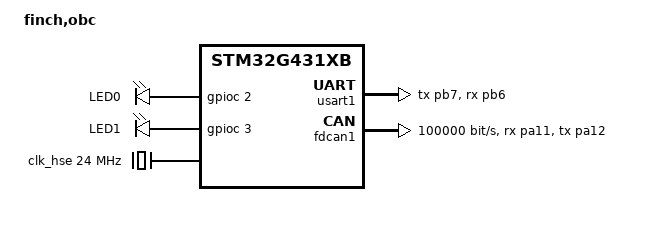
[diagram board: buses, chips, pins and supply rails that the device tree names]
/*
 * Copyright (c) 2025 The FINCH CubeSat Project Flight Software Contributors
 *
 * SPDX-License-Identifier: Apache-2.0
 */

/dts-v1/;

#include <st/g4/stm32g431Xb.dtsi>
#include <dt-bindings/pinctrl/stm32-pinctrl.h>
#include <zephyr/dt-bindings/clock/stm32g4_clock.h>

/ {
	model = "finch,obc";
	compatible = "finch,obc";

	chosen {
		zephyr,sram = &sram0;
		zephyr,flash = &flash0;
		zephyr,code-partition = &slot0_partition;
		zephyr,console = &usart1;
		zephyr,canbus = &fdcan1;
	};

	leds: leds {
		compatible = "gpio-leds";
		act_led: led_0 {
			gpios = <&gpioc 2 GPIO_ACTIVE_HIGH>;
			label = "LED0";
		};
		wrn_led: led_1 {
			gpios = <&gpioc 3 GPIO_ACTIVE_HIGH>;
			label = "LED1";
		};
	};

	aliases {
		led0 = &act_led;
		actled = &act_led;
		led1 = &wrn_led;
		wrnled = &wrn_led;
	};
};

&clk_hse {
	clock-frequency = <DT_FREQ_M(24)>;
	status = "okay";
};

&pll {
	div-m = <6>;
	mul-n = <85>;
	div-p = <7>;
	div-q = <2>;
	div-r = <2>;
	clocks = <&clk_hse>;
	status = "okay";
};

&rcc {
	clocks = <&pll>;
	clock-frequency = <DT_FREQ_M(170)>;
	ahb-prescaler = <1>;
	apb1-prescaler = <1>;
	apb2-prescaler = <1>;
	status = "okay";
};

&flash0 {
	partitions {
		compatible = "fixed-partitions";
		#address-cells = <1>;
		#size-cells = <1>;
		slot0_partition: partition@0 {
			label = "image-0";
			reg = <0x00000000 DT_SIZE_K(64)>;
		};
	};
};

&usart1 {
	pinctrl-0 = <&usart1_tx_pb7 &usart1_rx_pb6>;
	pinctrl-names = "default";
	status = "okay";
};

&fdcan1 {
	bitrate = <100000>;
	sample-point = <875>;
	clocks = <&rcc STM32_CLOCK_BUS_APB1 0x02000000>,
			<&rcc STM32_SRC_PLL_Q FDCAN_SEL(1)>;

	pinctrl-0 = <&fdcan1_rx_pa11 &fdcan1_tx_pa12>;
	pinctrl-names = "default";

	status = "okay";
};

&pinctrl {
	usart1_rx_pb6: usart1_rx_pb6 {
		pinmux = <STM32_PINMUX('B', 6, AF7)>;
	};

	usart1_tx_pb7: usart1_tx_pb7 {
		pinmux = <STM32_PINMUX('B', 7, AF7)>;
	};

	fdcan1_rx_pa11: fdcan1_rx_pa11 {
		pinmux = <STM32_PINMUX('A', 11, AF9)>;
	};

	fdcan1_tx_pa12: fdcan1_tx_pa12 {
		pinmux = <STM32_PINMUX('A', 12, AF9)>;
	};
};
